# f2838x_cm_mpu_regs register map
Vendor: Texas Instruments
Peripheral module from a debugger description file (folder C2000).
Address unit: 16 bits
Registers are 32-bit, read-write, no defined reset value unless marked. A register's access mark holds for its fields unless they carry their own. Offsets are as the file gives them; lines under a group give offsets from that group; [hi:lo] are bit positions; {n}, {i} and the like mark numbered series; 'fields as' and 'values as' point back to an identical list; <NAME> marks a mode.

## MPU_REGS — MPU Registers
0x00 MPU_CONTROL_REG — MPU control regster
  [0] ENABLE — Global Enable register
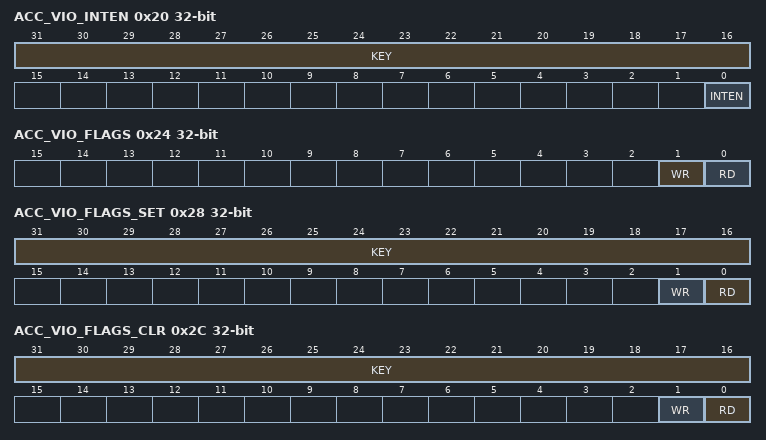
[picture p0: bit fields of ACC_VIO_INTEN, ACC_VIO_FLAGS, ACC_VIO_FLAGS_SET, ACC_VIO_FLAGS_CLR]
0x20 ACC_VIO_INTEN — Access violation interrupt enable
  [31:16] KEY — KEY to allow write access
  [0] INTEN — Interrupt enable register
0x24 ACC_VIO_FLAGS ro — Access violation flag register
  [1] WR — Write access violation flag
  [0] RD — Read access violation flag
0x28 ACC_VIO_FLAGS_SET — Acesss violation set register
  [31:16] KEY — KEY to allow write access
  [1] WR — Write access violation flag set
  [0] RD — Read access violation flag set
0x2C ACC_VIO_FLAGS_CLR — Access violation clear register
  [31:16] KEY — KEY to allow write access
  [1] WR — Write access violation flag clear
  [0] RD — Read access violation flag clear
0x30 ACC_VIO_ADDR_REG ro — Access violation address register
  [31:0] VIOLATION_ADDRESS
{0x40+8i} REGION{i}_STARTADDRESSS (i=0..4) — Region {i} start address register
  [31:0] START_ADDR — Start address of Region {i}
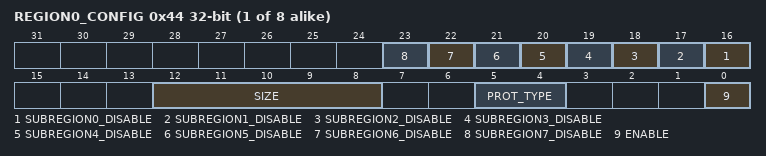
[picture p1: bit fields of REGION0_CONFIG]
{0x44+8i} REGION{i}_CONFIG (i=0..7) — Region {i} configuration register
  [n+16] SUBREGION{n}_DISABLE (n=0..7) — Sub region {n} disable bit
  [12:8] SIZE — Size of the region {i}
  [5:4] PROT_TYPE — Access permission configuration bits
  [0] ENABLE — Region Enable bit
0x68 REGION5_STARTADDRESSS — Region 5 start address register
  [31:0] START_ADDR — Start address of Region 4
0x70 REGION6_STARTADDRESSS — Region 6 start address register
  [31:0] START_ADDR — Start address of Region 6
0x78 REGION7_STARTADDRESSS — Region 7 start address register
  [31:0] START_ADDR — Start address of Region 7
